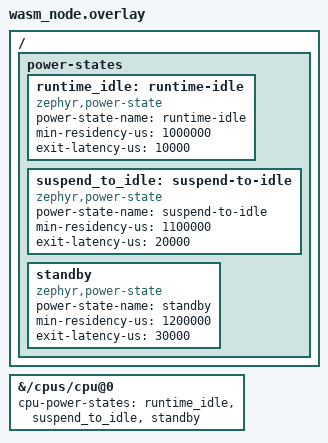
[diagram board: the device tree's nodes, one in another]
/*
 * SPDX-License-Identifier: Apache-2.0
 *
 * The three power states the sample chooses among, as native_sim's overlay
 * declares them: the sample's own pm.c enters and leaves them. Their
 * residencies sit just under the sample's 1.1, 1.2 and 1.3 s sleeps, so
 * each sleep picks the next state.
 */

/ {
	power-states {
		runtime_idle: runtime-idle {
			compatible = "zephyr,power-state";
			power-state-name = "runtime-idle";
			min-residency-us = <1000000>;
			exit-latency-us = <10000>;
		};

		suspend_to_idle: suspend-to-idle {
			compatible = "zephyr,power-state";
			power-state-name = "suspend-to-idle";
			min-residency-us = <1100000>;
			exit-latency-us = <20000>;
		};

		standby: standby {
			compatible = "zephyr,power-state";
			power-state-name = "standby";
			min-residency-us = <1200000>;
			exit-latency-us = <30000>;
		};
	};
};

&{/cpus/cpu@0} {
	cpu-power-states = <&runtime_idle &suspend_to_idle &standby>;
};
